# PIC32MK0128MCA032 device description
Architecture: MIPS; Family: PIC32MK; Series: PIC32MK
Registers are 32-bit, read-write, no defined reset value unless marked. A register's access mark holds for its fields unless they carry their own. Offsets are from the block's base; [hi:lo] are bit positions; {n}, {i} and the like mark numbered series; 'fields as' and 'values as' point back to an identical list.

## HLVD
Instances: HLVD 0x1f801800 in periph_pb1_std
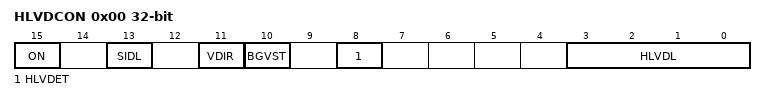
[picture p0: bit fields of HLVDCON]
0x00 HLVDCON — High/Low-Voltage Detect Control Register
  [15] ON — HLVD Module Enable bit
    1=HLVD module is enabled; 0=HLVD module is disabled
  [13] SIDL
  [11] VDIR — Voltage Change Direction Select bit
    1=Event occurs when voltage equals or exceeds the trip point (HLVDL); 0=Event occurs when voltage equals or falls below the trip point (HLVDL)
  [10] BGVST — Band Gap Reference Voltages Stable Status bit
    1=Indicates internal band gap voltage references is stable; 0=Indicates internal band gap voltage reference is not stable
  [8] HLVDET — High/Low-Voltage Detection Event Status bit
    1=Indicates HLVD Event interrupt is active; 0=Indicates HLVD Event interrupt is not active
  [3:0] HLVDL — High/Low-Voltage Detection Limit Select bits
    15=External LVDIN pin; 10=Selects Trip Point 2.40V (Typ.); 9=Selects Trip Point 2.50V (Typ.); 8=Selects Trip Point 2.697V (Typ.); 7=Selects Trip Point 2.791V (Typ.); 6=Selects Trip Point 3.0V (Typ.); 5=Selects Trip Point 3.288V (Typ.); 4=Selects Trip Point 3.529V (Typ.)
Value list HLVDCON__IRVST: 0x200=Indicates internal reference voltage references is stable; 0=Indicates internal reference voltage reference is not stable

## ICAP
Instances: ICAP 0x1f822000 in periph_pb2_std
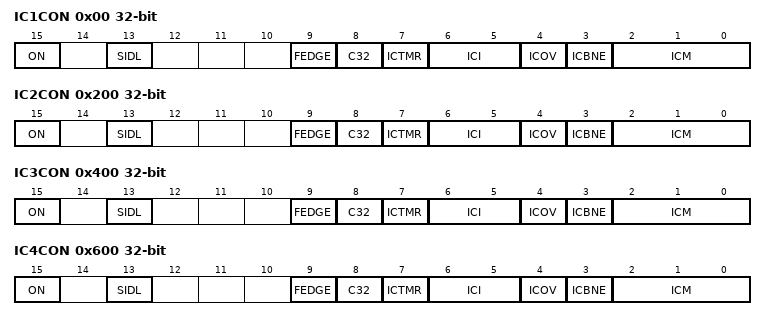
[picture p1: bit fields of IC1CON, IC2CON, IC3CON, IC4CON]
0x00 IC1CON — Input Capture 1 Control Register
  [15] ON — Input Capture Module Enable bit
    1=Module is enabled; 0=Disable and reset module, disable clocks, disable interrupt generation and allow SFR modifications
  [13] SIDL — Stop in Idle Control bit
    1=Halt in Idle mode; 0=Continue to operate in Idle mode
  [9] FEDGE — First Capture Edge Select bit
    1=Capture rising edge first; 0=Capture falling edge first
  [8] C32 — 32-bit Capture Select bit
    1=32-bit timer resource capture; 0=16-bit timer resource capture
  [7] ICTMR — Timer Select bit
    0=Timer3 is the counter source for capture; 1=Timer2 is the counter source for capture
  [6:5] ICI — Interrupt Control bits
    3=Interrupt on every fourth capture event; 2=Interrupt on every third capture event; 1=Interrupt on every second capture event; 0=Interrupt on every capture event
  [4] ICOV — Input Capture Overflow Status Flag bit (read-only)
    1=Input capture overflow has occurred; 0=No input capture overflow has occurred
  [3] ICBNE — Input Capture Buffer Not Empty Status bit (read-only)
    1=Input capture buffer is not empty; at least one more capture value can be read; 0=Input capture buffer is empty
  [2:0] ICM — Input Capture Mode Select bits
    7=Interrupt-Only mode (only supported while in Sleep mode or Idle mode); 6=Simple Capture Event mode every edge, specified edge first and every edge thereafter; 5=Prescaled Capture Event mode every sixteenth rising edge; 4=Prescaled Capture Event mode every fourth rising edge; 3=Simple Capture Event mode every rising edge; 2=Simple Capture Event mode every falling edge; 1=Edge Detect mode every edge (rising and falling); 0=Input Capture module is disabled
0x10 IC1BUF ro
0x200 IC2CON — Input Capture 1 Control Register
  fields as IC1CON
0x210 IC2BUF ro
0x400 IC3CON — Input Capture 1 Control Register
  fields as IC1CON
0x410 IC3BUF ro
0x600 IC4CON — Input Capture 1 Control Register
  fields as IC1CON
0x610 IC4BUF ro

## JTAG
Instances: JTAG 0x1f801000 in periph_pb1_std
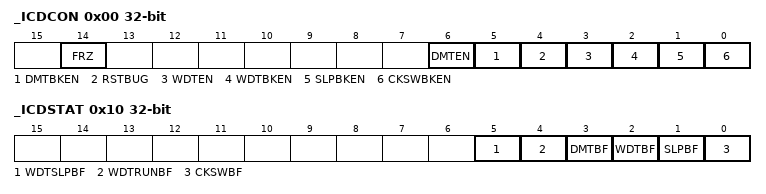
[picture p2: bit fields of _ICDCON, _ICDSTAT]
0x00 _ICDCON
  [14] FRZ, [6] DMTEN, [5] DMTBKEN, [4] RSTBUG, [3] WDTEN, [2] WDTBKEN, [1] SLPBKEN, [0] CKSWBKEN
0x10 _ICDSTAT
  [5] WDTSLPBF, [4] WDTRUNBF, [3] DMTBF, [2] WDTBF, [1] SLPBF, [0] CKSWBF

## NVM
Instances: NVM 0x1f800a00 in periph_pb1_std
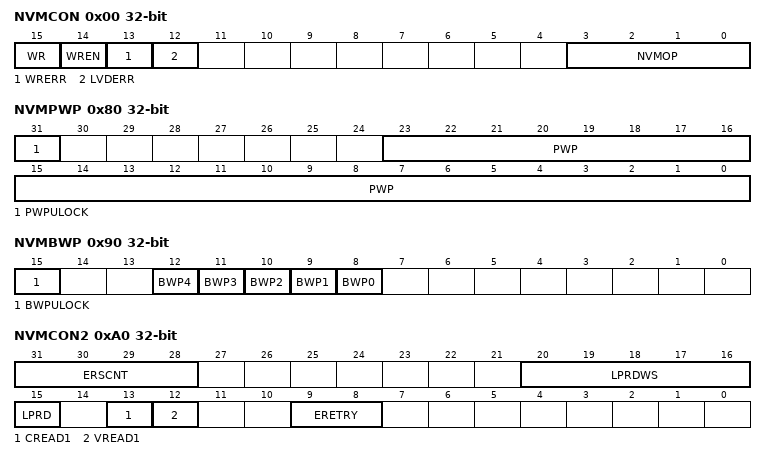
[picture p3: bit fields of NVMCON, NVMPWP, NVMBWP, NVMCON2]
0x00 NVMCON — Flash Programming Control Register
  [15] WR — Write Control bit
    1=Initiate a Flash operation; 0=Flash operation is complete or inactive
  [14] WREN — Write Enable bit
    1=Enable writes to the WR bit and disables writes to the NVMOP bits; 0=Disable writes to WR bit and enables writes to the NVMOP bits
  [13] WRERR — Write Error bit
    1=Program or erase sequence did not complete successfully; 0=Program or erase sequence completed normally
  [12] LVDERR — Low-Voltage Detect Error bit
    1=Low-voltage detected (possible data corruption if WRERR is set); 0=Voltage level is acceptable for programming
  [3:0] NVMOP — NVM Operation bits
    7=Program erase operation: erase all of program Flash memory (all pages must be unprotected); 5=Program Flash memory erase operation: erases all of Program Flash; 4=Page erase operation: erases page selected by NVMADDR; 3=Row program operation: programs row selected by NVMADDR; 2=Quad Word (128-bit) program operation: programs the 128-bit Flash word selected by NVMADDR; 1=Word program operation: programs word selected by NVMADDR; 0=No operation
0x10 NVMKEY wo
0x20 NVMADDR
{0x30+0x10*i} NVMDATA{i} (i=0..3)
0x70 NVMSRCADDR
0x80 NVMPWP
  [31] PWPULOCK, [23:0] PWP
0x90 NVMBWP — Flash Boot (Page) Write-Protect Register
  [15] BWPULOCK — Lower Boot Alias Write-protect Unlock bit
    1=LBWPx bits are not locked and can be modified; 0=LBWPx bits are locked and cannot be modified
  [n+8] BWP{n} (n=0..4) — Boot Alias Page {n} Write-protect bit
    1=Write protection for physical address {0x1FC00000+0x4000*n} through {0x1FC03FFF+0x4000*n} enabled; 0=Write protection for physical address {0x1FC00000+0x4000*n} through {0x1FC03FFF+0x4000*n} disabled
0xA0 NVMCON2 — Flash Programming Control Register 2
  [31:28] ERSCNT
  [20:16] LPRDWS — Wait State bits
    {v}={v} Wait States (v=0..31)
  [15] LPRD — Low-Power Read Control bit
    1=Configures Flash for Low Power reads, but with slower higher latency access times; 0=Configures Flash for faster Low Latency reads, but at higher power consumption
  [13] CREAD1 — Compare Read of Logic 1 bit
    1=Selects Erase Retry Procedure with Verify Read; 0=Selects Single Erase w/o Verify Read
  [12] VREAD1 — Verify Read of Logic 1 Control bit
    values as CREAD1
  [9:8] ERETRY — Erase Retry Control bits
    3=Erase strength for last retry cycle; 2=Erase strength for third retry cycle; 1=Erase strength for second retry cycle; 0=Erase strength for first retry cycle
Value list NVMPWP__PWPULOCK: 1=Register is not locked and can be modified; 0=Register is locked and cannot be modified
